AUTOSAR XML (schema 4-2-2)
package /AUTOLIV/SoftwareComponents/PRE
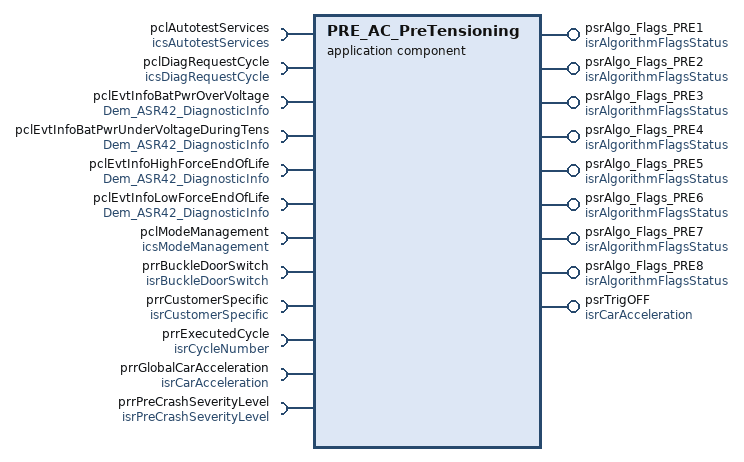
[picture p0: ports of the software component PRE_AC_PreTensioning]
  application sw component type PRE_AC_PreTensioning: category=SWC
    12 x require port:
      pclAutotestServices: required-com-specs=[GetTestResult, GetLastCriticalAutotestID], required-interface=icsAutotestServices
      pclDiagRequestCycle: required-com-specs=[GetDiagRequestCycle, ClearDiagRequestCycle], required-interface=icsDiagRequestCycle
      pclEvtInfoBatPwrOverVoltage: required-interface=Dem_ASR42_DiagnosticInfo
        required-com-specs:
          GetEventStatus
          GetEventFailed
          GetEventTested
          GetDTCOfEvent
          GetFaultDetectionCounter
          GetEventFreezeFrameData
          GetEventExtendedDataRecord
      pclEvtInfoBatPwrUnderVoltageDuringTens: required-interface=Dem_ASR42_DiagnosticInfo
        required-com-specs:
          GetEventStatus
          GetEventFailed
          GetEventTested
          GetDTCOfEvent
          GetFaultDetectionCounter
          GetEventFreezeFrameData
          GetEventExtendedDataRecord
      pclEvtInfoHighForceEndOfLife: required-interface=Dem_ASR42_DiagnosticInfo
        required-com-specs:
          GetEventStatus
          GetEventFailed
          GetEventTested
          GetDTCOfEvent
          GetFaultDetectionCounter
          GetEventFreezeFrameData
          GetEventExtendedDataRecord
      pclEvtInfoLowForceEndOfLife: required-interface=Dem_ASR42_DiagnosticInfo
        required-com-specs:
          GetEventStatus
          GetEventFailed
          GetEventTested
          GetDTCOfEvent
          GetFaultDetectionCounter
          GetEventFreezeFrameData
          GetEventExtendedDataRecord
      pclModeManagement: client-com-spec=CheckModeStatus, required-interface=icsModeManagement
      prrBuckleDoorSwitch: required-interface=isrBuckleDoorSwitch
        required-com-specs:
          data-element=u8BuckleSwitch, uses-end-to-end-protection=0, init-value=constant-reference=APPLINIT_KU8_BUCKLE_SWITCH_STATUS_NOT_DEFINED
          data-element=u8DoorSwitch, uses-end-to-end-protection=0, init-value=constant-reference=APPLINIT_KU8_DOOR_SWITCH_STATUS_NOT_DEFINED
      prrCustomerSpecific: required-interface=isrCustomerSpecific
        required-com-specs:
          data-element=b8IsCarCrashDetected, uses-end-to-end-protection=0, init-value=constant-reference=APPLINIT_KB8_CAR_CRASH_DETECTED_FALSE
          data-element=b8IsCarCrankingActive, uses-end-to-end-protection=0, init-value=constant-reference=APPLINIT_KB8_CAR_CRANKING_ACTIVE_TRUE
          data-element=u8BeltSlackStatus, uses-end-to-end-protection=0, init-value=constant-reference=APPLINIT_KU8_BELT_SLACK_STATUS_NOT_DEFINED
          data-element=u8PreCrashRequest, uses-end-to-end-protection=0, init-value=constant-reference=APPLINIT_KU8_PRE_CRASH_REQUEST_NO_REQUEST
          data-element=b8PreCrashRequestEnable, uses-end-to-end-protection=0, init-value=constant-reference=APPLINIT_KB8_BOOLEAN_FALSE
          data-element=u8HapticRequest, uses-end-to-end-protection=0, init-value=constant-reference=APPLINIT_KU8_HAPTIC_REQUEST_NO
      prrExecutedCycle: nonqueued-receiver-com-spec{data-element=u8CycleNumber, uses-end-to-end-protection=0, init-value=constant-reference=APPLINIT_KU8_CYCLE_NUMBER_NONE}, required-interface=isrCycleNumber
      prrGlobalCarAcceleration: nonqueued-receiver-com-spec{data-element=b8IsCarAccelerationLow, uses-end-to-end-protection=0, init-value=constant-reference=APPLINIT_KB8_CAR_ACCEL_LOW_TRUE}, required-interface=isrCarAcceleration
      prrPreCrashSeverityLevel: nonqueued-receiver-com-spec{data-element=u8PreCrashSeverityLevel, uses-end-to-end-protection=0, init-value=constant-reference=APPLINIT_KU8_PRE_CRASH_SEVERITY_LEVEL_NO}, required-interface=isrPreCrashSeverityLevel
    9 x provide port:
      psrAlgo_Flags_PRE1: provided-interface=isrAlgorithmFlagsStatus
        provided-com-specs:
          data-element=b8InterruptFlag, uses-end-to-end-protection=0, init-value=constant-reference=APPLINIT_KB8_ALGO_FLAG_FALSE
          data-element=b8PreActivationFlag, uses-end-to-end-protection=1, init-value=constant-reference=APPLINIT_KB8_ALGO_FLAG_FALSE
          data-element=b8PreConditionsFlag, uses-end-to-end-protection=1, init-value=constant-reference=APPLINIT_KB8_ALGO_FLAG_FALSE
          data-element=u8TriggeringSource, uses-end-to-end-protection=1, init-value=constant-reference=APPLINIT_KU8_TRIGGERING_SOURCE_NO
          data-element=b8TriggerFlag, uses-end-to-end-protection=1, init-value=constant-reference=APPLINIT_KB8_ALGO_FLAG_FALSE
      psrAlgo_Flags_PRE2: provided-interface=isrAlgorithmFlagsStatus
        provided-com-specs:
          data-element=b8TriggerFlag, uses-end-to-end-protection=1, init-value=constant-reference=APPLINIT_KB8_ALGO_FLAG_FALSE
          data-element=b8InterruptFlag, uses-end-to-end-protection=1, init-value=constant-reference=APPLINIT_KB8_ALGO_FLAG_FALSE
          data-element=u8TriggeringSource, uses-end-to-end-protection=1, init-value=constant-reference=APPLINIT_KU8_TRIGGERING_SOURCE_NO
          data-element=b8PreActivationFlag, uses-end-to-end-protection=1, init-value=constant-reference=APPLINIT_KB8_ALGO_FLAG_FALSE
          data-element=b8PreConditionsFlag, uses-end-to-end-protection=1, init-value=constant-reference=APPLINIT_KB8_ALGO_FLAG_FALSE
      psrAlgo_Flags_PRE3: provided-interface=isrAlgorithmFlagsStatus
        provided-com-specs:
          data-element=b8TriggerFlag, uses-end-to-end-protection=1, init-value=constant-reference=APPLINIT_KB8_ALGO_FLAG_FALSE
          data-element=b8PreConditionsFlag, uses-end-to-end-protection=1, init-value=constant-reference=APPLINIT_KB8_ALGO_FLAG_FALSE
          data-element=b8InterruptFlag, uses-end-to-end-protection=1, init-value=constant-reference=APPLINIT_KB8_ALGO_FLAG_FALSE
          data-element=b8PreActivationFlag, uses-end-to-end-protection=1, init-value=constant-reference=APPLINIT_KB8_ALGO_FLAG_FALSE
          data-element=u8TriggeringSource, uses-end-to-end-protection=1, init-value=constant-reference=APPLINIT_KU8_TRIGGERING_SOURCE_NO
      psrAlgo_Flags_PRE4: provided-interface=isrAlgorithmFlagsStatus
        provided-com-specs:
          data-element=b8PreConditionsFlag, uses-end-to-end-protection=1, init-value=constant-reference=APPLINIT_KB8_ALGO_FLAG_FALSE
          data-element=b8PreActivationFlag, uses-end-to-end-protection=1, init-value=constant-reference=APPLINIT_KB8_ALGO_FLAG_FALSE
          data-element=b8InterruptFlag, uses-end-to-end-protection=1, init-value=constant-reference=APPLINIT_KB8_ALGO_FLAG_FALSE
          data-element=b8TriggerFlag, uses-end-to-end-protection=1, init-value=constant-reference=APPLINIT_KB8_ALGO_FLAG_FALSE
          data-element=u8TriggeringSource, uses-end-to-end-protection=1, init-value=constant-reference=APPLINIT_KU8_TRIGGERING_SOURCE_NO
      psrAlgo_Flags_PRE5: provided-interface=isrAlgorithmFlagsStatus
        provided-com-specs:
          data-element=b8PreActivationFlag, uses-end-to-end-protection=1, init-value=constant-reference=APPLINIT_KB8_ALGO_FLAG_FALSE
          data-element=b8TriggerFlag, uses-end-to-end-protection=1, init-value=constant-reference=APPLINIT_KB8_ALGO_FLAG_FALSE
          data-element=u8TriggeringSource, uses-end-to-end-protection=1, init-value=constant-reference=APPLINIT_KU8_TRIGGERING_SOURCE_NO
          data-element=b8InterruptFlag, uses-end-to-end-protection=1, init-value=constant-reference=APPLINIT_KB8_ALGO_FLAG_FALSE
          data-element=b8PreConditionsFlag, uses-end-to-end-protection=1, init-value=constant-reference=APPLINIT_KB8_ALGO_FLAG_FALSE
      psrAlgo_Flags_PRE6: provided-interface=isrAlgorithmFlagsStatus
        provided-com-specs:
          data-element=u8TriggeringSource, uses-end-to-end-protection=1, init-value=constant-reference=APPLINIT_KU8_TRIGGERING_SOURCE_NO
          data-element=b8PreConditionsFlag, uses-end-to-end-protection=1, init-value=constant-reference=APPLINIT_KB8_ALGO_FLAG_FALSE
          data-element=b8PreActivationFlag, uses-end-to-end-protection=1, init-value=constant-reference=APPLINIT_KB8_ALGO_FLAG_FALSE
          data-element=b8TriggerFlag, uses-end-to-end-protection=1, init-value=constant-reference=APPLINIT_KB8_ALGO_FLAG_FALSE
          data-element=b8InterruptFlag, uses-end-to-end-protection=1, init-value=constant-reference=APPLINIT_KB8_ALGO_FLAG_FALSE
      psrAlgo_Flags_PRE7: provided-interface=isrAlgorithmFlagsStatus
        provided-com-specs:
          data-element=u8TriggeringSource, uses-end-to-end-protection=1, init-value=constant-reference=APPLINIT_KU8_TRIGGERING_SOURCE_NO
          data-element=b8InterruptFlag, uses-end-to-end-protection=1, init-value=constant-reference=APPLINIT_KB8_ALGO_FLAG_FALSE
          data-element=b8PreConditionsFlag, uses-end-to-end-protection=1, init-value=constant-reference=APPLINIT_KB8_ALGO_FLAG_FALSE
          data-element=b8PreActivationFlag, uses-end-to-end-protection=1, init-value=constant-reference=APPLINIT_KB8_ALGO_FLAG_FALSE
          data-element=b8TriggerFlag, uses-end-to-end-protection=1, init-value=constant-reference=APPLINIT_KB8_ALGO_FLAG_FALSE
      psrAlgo_Flags_PRE8: provided-interface=isrAlgorithmFlagsStatus
        provided-com-specs:
          data-element=b8InterruptFlag, uses-end-to-end-protection=1, init-value=constant-reference=APPLINIT_KB8_ALGO_FLAG_FALSE
          data-element=b8TriggerFlag, uses-end-to-end-protection=1, init-value=constant-reference=APPLINIT_KB8_ALGO_FLAG_FALSE
          data-element=b8PreConditionsFlag, uses-end-to-end-protection=1, init-value=constant-reference=APPLINIT_KB8_ALGO_FLAG_FALSE
          data-element=b8PreActivationFlag, uses-end-to-end-protection=1, init-value=constant-reference=APPLINIT_KB8_ALGO_FLAG_FALSE
          data-element=u8TriggeringSource, uses-end-to-end-protection=1, init-value=constant-reference=APPLINIT_KU8_TRIGGERING_SOURCE_NO
      psrTrigOFF: nonqueued-sender-com-spec{data-element=b8IsCarAccelerationLow, uses-end-to-end-protection=1, init-value=constant-reference=APPLINIT_KB8_CAR_ACCEL_LOW_TRUE}, provided-interface=isrCarAcceleration
